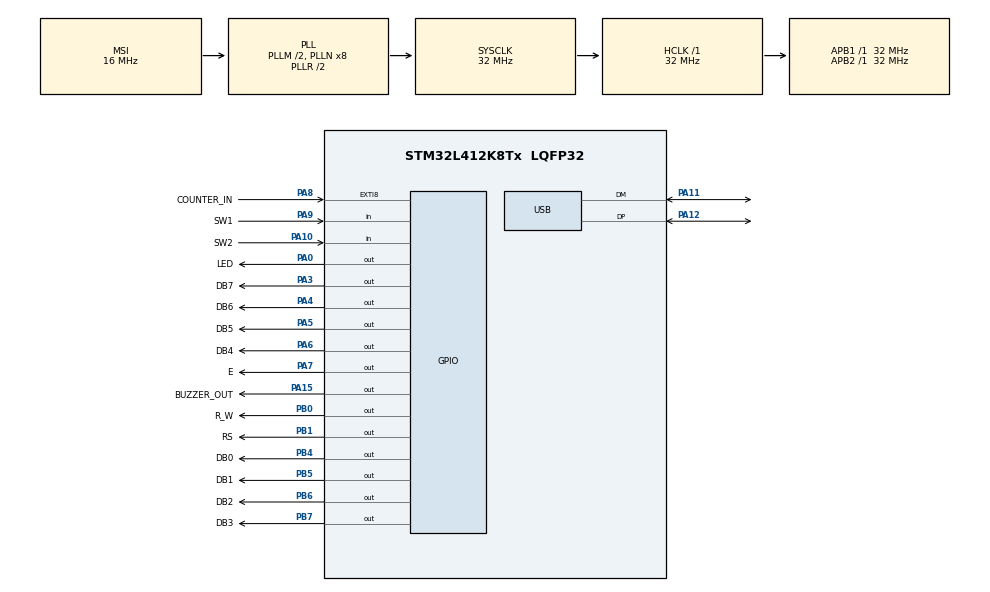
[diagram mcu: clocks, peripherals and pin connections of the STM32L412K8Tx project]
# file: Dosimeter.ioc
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Mcu.Family=STM32L4
Mcu.Name=STM32L412K8Tx
Mcu.Package=LQFP32
NVIC.PriorityGroup=NVIC_PRIORITYGROUP_4
PA0-CK_IN.GPIO_Label=LED
PA0-CK_IN.Signal=GPIO_Output
PA10.GPIO_Label=SW2
PA10.Signal=GPIO_Input
PA11.Mode=Device
PA11.Signal=USB_DM
PA12.Mode=Device
PA12.Signal=USB_DP
PA13\ (JTMS/SWDIO).Mode=Serial_Wire
PA13\ (JTMS/SWDIO).Signal=SYS_JTMS-SWDIO
PA14\ (JTCK/SWCLK).Mode=Serial_Wire
PA14\ (JTCK/SWCLK).Signal=SYS_JTCK-SWCLK
PA15\ (JTDI).GPIO_Label=BUZZER_OUT
PA15\ (JTDI).Signal=GPIO_Output
PA3.GPIO_Label=DB7
PA3.Signal=GPIO_Output
PA4.GPIO_Label=DB6
PA4.Signal=GPIO_Output
PA5.GPIO_Label=DB5
PA5.Signal=GPIO_Output
PA6.GPIO_Label=DB4
PA6.Signal=GPIO_Output
PA7.GPIO_Label=E
PA7.Signal=GPIO_Output
PA8.GPIO_Label=COUNTER_IN
PA8.Signal=GPXTI8
PA9.GPIO_Label=SW1
PA9.Signal=GPIO_Input
PB0.GPIO_Label=R_W
PB0.Signal=GPIO_Output
PB1.GPIO_Label=RS
PB1.Signal=GPIO_Output
PB4\ (NJTRST).GPIO_Label=DB0
PB4\ (NJTRST).Signal=GPIO_Output
PB5.GPIO_Label=DB1
PB5.Signal=GPIO_Output
PB6.GPIO_Label=DB2
PB6.Signal=GPIO_Output
PB7.GPIO_Label=DB3
PB7.Signal=GPIO_Output
ProjectManager.HeapSize=0x200
ProjectManager.StackSize=0x400
ProjectManager.TargetToolchain=STM32CubeIDE
RCC.ADCFreq_Value=32000000
RCC.AHBFreq_Value=32000000
RCC.APB1Freq_Value=32000000
RCC.APB1TimFreq_Value=32000000
RCC.APB2Freq_Value=32000000
RCC.APB2TimFreq_Value=32000000
RCC.CK48CLockSelection=RCC_USBCLKSOURCE_HSI48
RCC.CortexFreq_Value=32000000
RCC.HCLKFreq_Value=32000000
RCC.HSE_VALUE=8000000
RCC.HSI48_VALUE=48000000
RCC.HSI_VALUE=16000000
RCC.LSE_VALUE=32768
RCC.MSIClockRange=RCC_MSIRANGE_8
RCC.MSI_VALUE=16000000
RCC.PLLM=2
RCC.SYSCLKFreq_VALUE=32000000
RCC.SYSCLKSource=RCC_SYSCLKSOURCE_PLLCLK
RCC.USBFreq_Value=48000000
RCC.VCOOutputFreq_Value=64000000
TIM6.Period=64000
TIM6.Prescaler=10
VP_TIM6_VS_ClockSourceINT.Mode=Enable_Timer
board=custom

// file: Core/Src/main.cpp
/* USER CODE BEGIN Header */
/**
  ******************************************************************************
  * @file           : main.c
  * @brief          : Main program body
  ******************************************************************************
  * @attention
  *
  * <h2><center>&copy; Copyright (c) 2020 STMicroelectronics.
  * All rights reserved.</center></h2>
  *
  * This software component is licensed by ST under BSD 3-Clause license,
  * the "License"; You may not use this file except in compliance with the
  * License. You may obtain a copy of the License at:
  *                        opensource.org/licenses/BSD-3-Clause
  *
  ******************************************************************************
  */
/* USER CODE END Header */
#include "main.h"
#include "tim.h"
#include "usb.h"
#include "gpio.h"

/* USER CODE BEGIN Includes */
#include "appMain/appMain.h"
/* USER CODE END Includes */

/* USER CODE BEGIN PTD */
static Main mainCpp;
/* USER CODE END PTD */

void SystemClock_Config(void);

int main(void)
{

  /* MCU Configuration--------------------------------------------------------*/

  /* Reset of all peripherals, Initializes the Flash interface and the Systick. */
  HAL_Init();

  /* Configure the system clock */
  SystemClock_Config();

  /* Initialize all configured peripherals */
  MX_GPIO_Init();
  MX_TIM6_Init();
  MX_USB_PCD_Init();
  /* USER CODE BEGIN 2 */

  mainCpp.appMain();
  /* USER CODE END 2 */

  /* Infinite loop */
  while (1)
  {

  }
}

void SystemClock_Config(void)
{
  RCC_OscInitTypeDef RCC_OscInitStruct = {0};
  RCC_ClkInitTypeDef RCC_ClkInitStruct = {0};
  RCC_PeriphCLKInitTypeDef PeriphClkInit = {0};

  /** Configure the main internal regulator output voltage
  */
  if (HAL_PWREx_ControlVoltageScaling(PWR_REGULATOR_VOLTAGE_SCALE1) != HAL_OK)
  {
    Error_Handler();
  }
  /** Initializes the RCC Oscillators according to the specified parameters
  * in the RCC_OscInitTypeDef structure.
  */
  RCC_OscInitStruct.OscillatorType = RCC_OSCILLATORTYPE_HSI48|RCC_OSCILLATORTYPE_MSI;
  RCC_OscInitStruct.HSI48State = RCC_HSI48_ON;
  RCC_OscInitStruct.MSIState = RCC_MSI_ON;
  RCC_OscInitStruct.MSICalibrationValue = 0;
  RCC_OscInitStruct.MSIClockRange = RCC_MSIRANGE_8;
  RCC_OscInitStruct.PLL.PLLState = RCC_PLL_ON;
  RCC_OscInitStruct.PLL.PLLSource = RCC_PLLSOURCE_MSI;
  RCC_OscInitStruct.PLL.PLLM = 2;
  RCC_OscInitStruct.PLL.PLLN = 8;
  RCC_OscInitStruct.PLL.PLLQ = RCC_PLLQ_DIV2;
  RCC_OscInitStruct.PLL.PLLR = RCC_PLLR_DIV2;
  if (HAL_RCC_OscConfig(&RCC_OscInitStruct) != HAL_OK)
  {
    Error_Handler();
  }
  /** Initializes the CPU, AHB and APB buses clocks
  */
  RCC_ClkInitStruct.ClockType = RCC_CLOCKTYPE_HCLK|RCC_CLOCKTYPE_SYSCLK
                              |RCC_CLOCKTYPE_PCLK1|RCC_CLOCKTYPE_PCLK2;
  RCC_ClkInitStruct.SYSCLKSource = RCC_SYSCLKSOURCE_PLLCLK;
  RCC_ClkInitStruct.AHBCLKDivider = RCC_SYSCLK_DIV1;
  RCC_ClkInitStruct.APB1CLKDivider = RCC_HCLK_DIV1;
  RCC_ClkInitStruct.APB2CLKDivider = RCC_HCLK_DIV1;

  if (HAL_RCC_ClockConfig(&RCC_ClkInitStruct, FLASH_LATENCY_1) != HAL_OK)
  {
    Error_Handler();
  }
  PeriphClkInit.PeriphClockSelection = RCC_PERIPHCLK_USB;
  PeriphClkInit.UsbClockSelection = RCC_USBCLKSOURCE_HSI48;
  if (HAL_RCCEx_PeriphCLKConfig(&PeriphClkInit) != HAL_OK)
  {
    Error_Handler();
  }
}

void Error_Handler(void)
{
}

/************************ (C) COPYRIGHT STMicroelectronics *****END OF FILE****/
